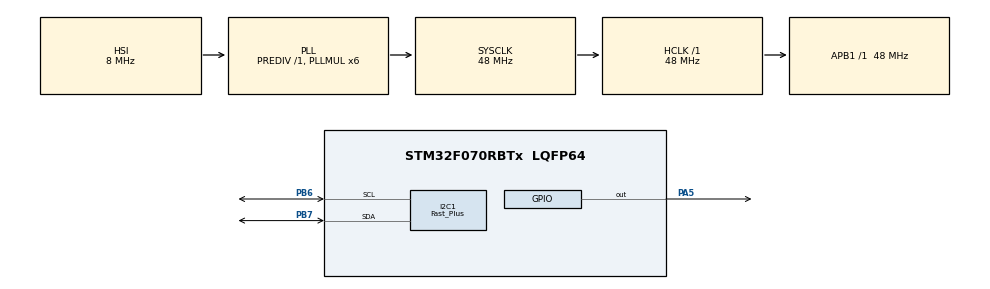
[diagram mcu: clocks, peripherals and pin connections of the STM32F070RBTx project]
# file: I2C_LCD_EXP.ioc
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I2C1.I2C_Speed_Mode=I2C_Fast_Plus
I2C1.Timing=0x00000001
Mcu.Family=STM32F0
Mcu.Name=STM32F070RBTx
Mcu.Package=LQFP64
PA5.GPIO_Speed=GPIO_SPEED_FREQ_HIGH
PA5.Signal=GPIO_Output
PB6.Mode=I2C
PB6.Signal=I2C1_SCL
PB7.Mode=I2C
PB7.Signal=I2C1_SDA
ProjectManager.HeapSize=0x200
ProjectManager.StackSize=0x400
ProjectManager.TargetToolchain=STM32CubeIDE
RCC.AHBFreq_Value=48000000
RCC.APB1Freq_Value=48000000
RCC.APB1TimFreq_Value=48000000
RCC.HCLKFreq_Value=48000000
RCC.PLLMUL=RCC_PLL_MUL6
RCC.SYSCLKFreq_VALUE=48000000
RCC.SYSCLKSource=RCC_SYSCLKSOURCE_PLLCLK
board=custom

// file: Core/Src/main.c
/* USER CODE BEGIN Header */
/**
  ******************************************************************************
  * @file           : main.c
  * @brief          : Main program body
  ******************************************************************************
  * @attention
  *
  * <h2><center>&copy; Copyright (c) 2020 STMicroelectronics.
  * All rights reserved.</center></h2>
  *
  * This software component is licensed by ST under BSD 3-Clause license,
  * the "License"; You may not use this file except in compliance with the
  * License. You may obtain a copy of the License at:
  *                        opensource.org/licenses/BSD-3-Clause
  *
  ******************************************************************************
  */
/* USER CODE END Header */

#include "main.h"

/* USER CODE BEGIN Includes */

#include "lcd_i2cModule.h"

#define		MY_DEVİCE_ADDRESS		0x45

/* USER CODE END Includes */

I2C_HandleTypeDef hi2c1;

void SystemClock_Config(void);
static void MX_GPIO_Init(void);
static void MX_I2C1_Init(void);

int main(void)
{

  /* MCU Configuration--------------------------------------------------------*/

  /* Reset of all peripherals, Initializes the Flash interface and the Systick. */
  HAL_Init();

  /* Configure the system clock */
  SystemClock_Config();

  /* Initialize all configured peripherals */
  MX_GPIO_Init();
  MX_I2C1_Init();
  /* USER CODE BEGIN 2 */

 LCD_i2cDeviceCheck();
 LCD_Init();
 LCD_BackLight(LCD_BL_ON);
 LCD_SetCursor(1, 1);

  /* USER CODE END 2 */
float a=0.0;
  /* Infinite loop */
  while (1)
  {

    /* USER CODE BEGIN 3 */

	  LCD_Print("hello",a);

  }
  /* USER CODE END 3 */
}

void SystemClock_Config(void)
{
  RCC_OscInitTypeDef RCC_OscInitStruct = {0};
  RCC_ClkInitTypeDef RCC_ClkInitStruct = {0};
  RCC_PeriphCLKInitTypeDef PeriphClkInit = {0};

  /** Initializes the CPU, AHB and APB busses clocks
  */
  RCC_OscInitStruct.OscillatorType = RCC_OSCILLATORTYPE_HSI;
  RCC_OscInitStruct.HSIState = RCC_HSI_ON;
  RCC_OscInitStruct.HSICalibrationValue = RCC_HSICALIBRATION_DEFAULT;
  RCC_OscInitStruct.PLL.PLLState = RCC_PLL_ON;
  RCC_OscInitStruct.PLL.PLLSource = RCC_PLLSOURCE_HSI;
  RCC_OscInitStruct.PLL.PLLMUL = RCC_PLL_MUL6;
  RCC_OscInitStruct.PLL.PREDIV = RCC_PREDIV_DIV1;
  if (HAL_RCC_OscConfig(&RCC_OscInitStruct) != HAL_OK)
  {
    Error_Handler();
  }
  /** Initializes the CPU, AHB and APB busses clocks
  */
  RCC_ClkInitStruct.ClockType = RCC_CLOCKTYPE_HCLK|RCC_CLOCKTYPE_SYSCLK
                              |RCC_CLOCKTYPE_PCLK1;
  RCC_ClkInitStruct.SYSCLKSource = RCC_SYSCLKSOURCE_PLLCLK;
  RCC_ClkInitStruct.AHBCLKDivider = RCC_SYSCLK_DIV1;
  RCC_ClkInitStruct.APB1CLKDivider = RCC_HCLK_DIV1;

  if (HAL_RCC_ClockConfig(&RCC_ClkInitStruct, FLASH_LATENCY_1) != HAL_OK)
  {
    Error_Handler();
  }
  PeriphClkInit.PeriphClockSelection = RCC_PERIPHCLK_I2C1;
  PeriphClkInit.I2c1ClockSelection = RCC_I2C1CLKSOURCE_HSI;
  if (HAL_RCCEx_PeriphCLKConfig(&PeriphClkInit) != HAL_OK)
  {
    Error_Handler();
  }
}

static void MX_I2C1_Init(void)
{

  hi2c1.Instance = I2C1;
  hi2c1.Init.Timing = 0x00000001;
  hi2c1.Init.OwnAddress1 = 0;
  hi2c1.Init.AddressingMode = I2C_ADDRESSINGMODE_7BIT;
  hi2c1.Init.DualAddressMode = I2C_DUALADDRESS_DISABLE;
  hi2c1.Init.OwnAddress2 = 0;
  hi2c1.Init.OwnAddress2Masks = I2C_OA2_NOMASK;
  hi2c1.Init.GeneralCallMode = I2C_GENERALCALL_DISABLE;
  hi2c1.Init.NoStretchMode = I2C_NOSTRETCH_DISABLE;
  if (HAL_I2C_Init(&hi2c1) != HAL_OK)
  {
    Error_Handler();
  }
  /** Configure Analogue filter
  */
  if (HAL_I2CEx_ConfigAnalogFilter(&hi2c1, I2C_ANALOGFILTER_ENABLE) != HAL_OK)
  {
    Error_Handler();
  }
  /** Configure Digital filter
  */
  if (HAL_I2CEx_ConfigDigitalFilter(&hi2c1, 0) != HAL_OK)
  {
    Error_Handler();
  }
  /** I2C Fast mode Plus enable
  */
  __HAL_SYSCFG_FASTMODEPLUS_ENABLE(I2C_FASTMODEPLUS_I2C1);

}

static void MX_GPIO_Init(void)
{
  GPIO_InitTypeDef GPIO_InitStruct = {0};

  /* GPIO Ports Clock Enable */
  __HAL_RCC_GPIOA_CLK_ENABLE();
  __HAL_RCC_GPIOB_CLK_ENABLE();

  /*Configure GPIO pin Output Level */
  HAL_GPIO_WritePin(GPIOA, GPIO_PIN_5, GPIO_PIN_RESET);

  /*Configure GPIO pin : PA5 */
  GPIO_InitStruct.Pin = GPIO_PIN_5;
  GPIO_InitStruct.Mode = GPIO_MODE_OUTPUT_PP;
  GPIO_InitStruct.Pull = GPIO_NOPULL;
  GPIO_InitStruct.Speed = GPIO_SPEED_FREQ_HIGH;
  HAL_GPIO_Init(GPIOA, &GPIO_InitStruct);

}

void Error_Handler(void)
{
}

/************************ (C) COPYRIGHT STMicroelectronics *****END OF FILE****/
